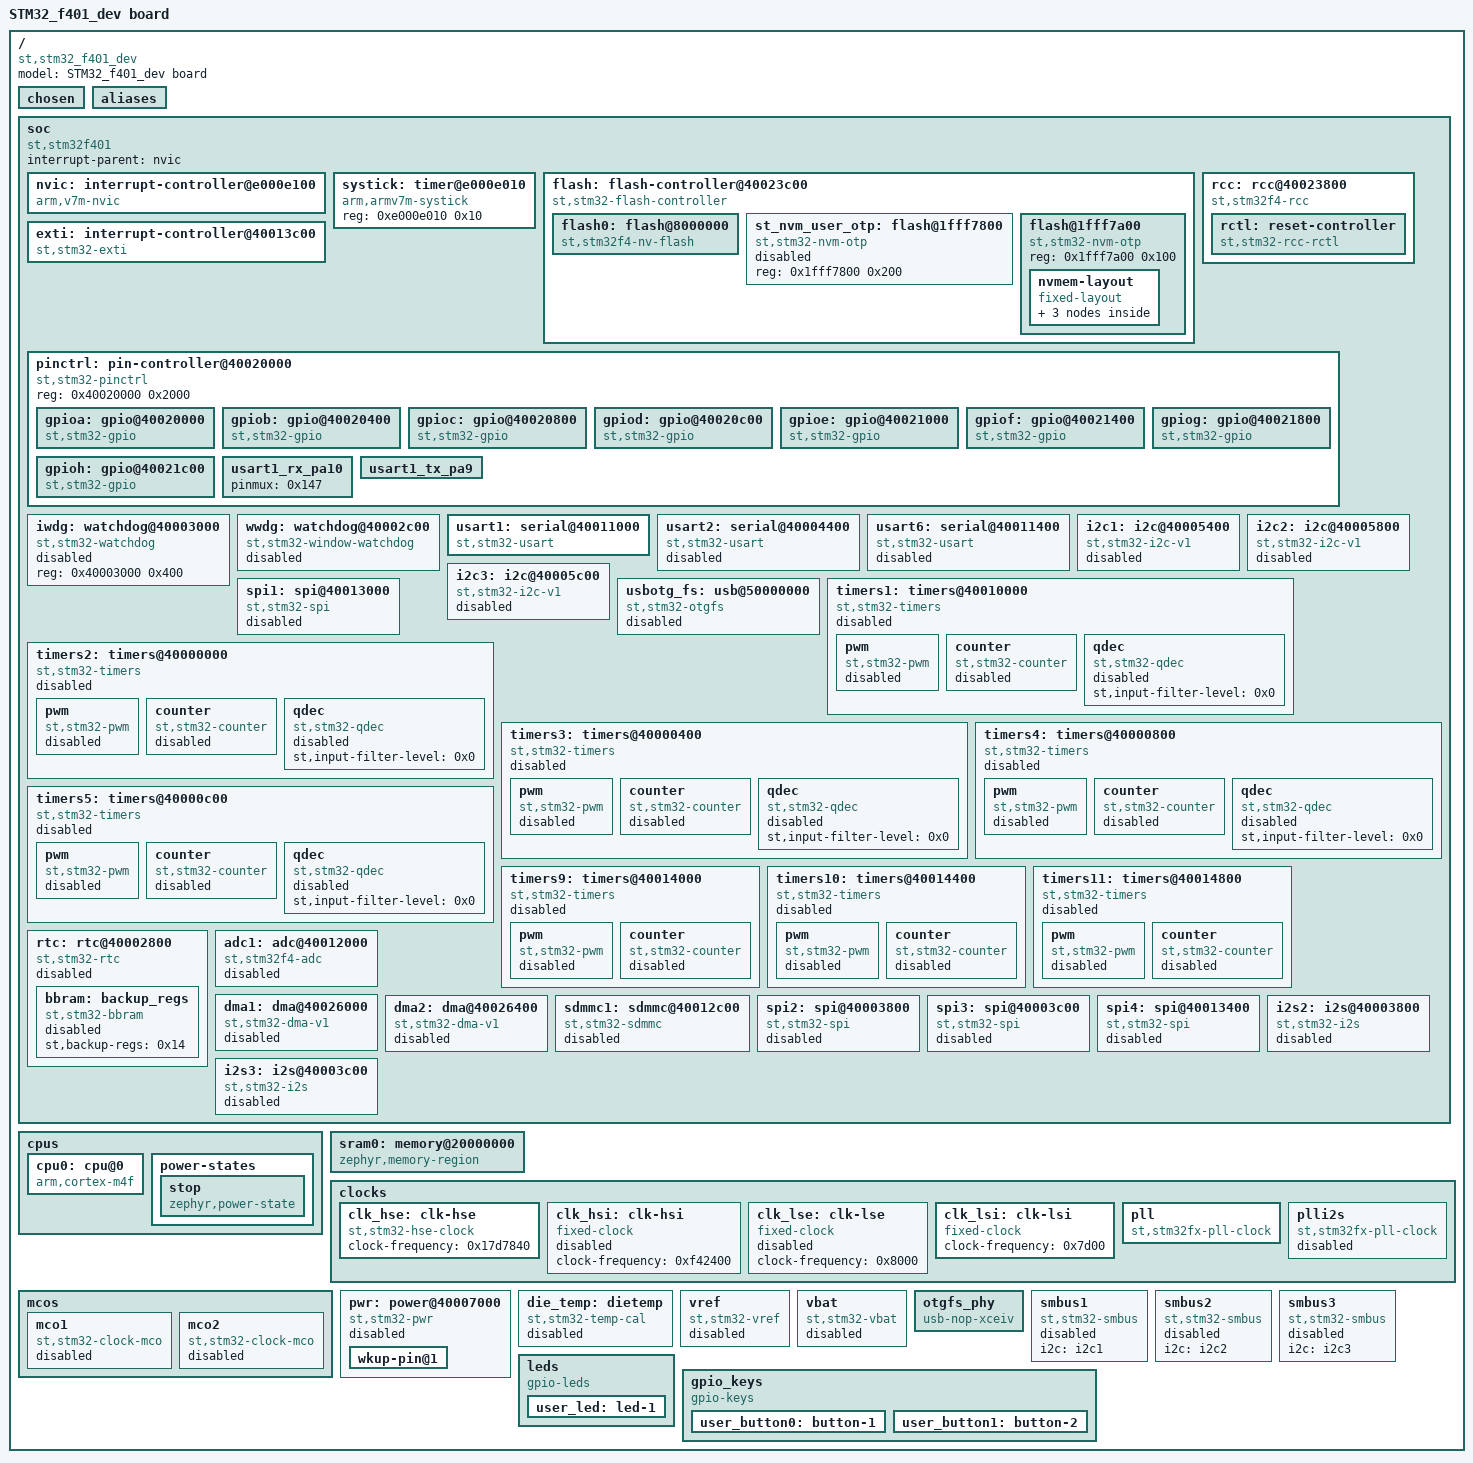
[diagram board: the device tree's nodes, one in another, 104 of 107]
/dts-v1/;

/* node '/' defined in zephyr/dts/common/skeleton.dtsi:9 */
/ {
	#address-cells = < 0x1 >;         /* in zephyr/dts/common/skeleton.dtsi:10 */
	#size-cells = < 0x1 >;            /* in zephyr/dts/common/skeleton.dtsi:11 */
	model = "STM32_f401_dev board";   /* in ../STM32_F401_Basic_Framework/boards/others/stm32_f401_dev/stm32_f401_dev.dts:8 */
	compatible = "st,stm32_f401_dev"; /* in ../STM32_F401_Basic_Framework/boards/others/stm32_f401_dev/stm32_f401_dev.dts:9 */

	/* node '/chosen' defined in zephyr/dts/common/skeleton.dtsi:13 */
	chosen {
		zephyr,flash-controller = &flash;     /* in zephyr/dts/arm/st/f4/stm32f4.dtsi:26 */
		zephyr,system-timer-companion = &rtc; /* in zephyr/dts/arm/st/f4/stm32f4.dtsi:27 */
		zephyr,console = &usart1;             /* in ../STM32_F401_Basic_Framework/boards/others/stm32_f401_dev/stm32_f401_dev.dts:12 */
		zephyr,shell-uart = &usart1;          /* in ../STM32_F401_Basic_Framework/boards/others/stm32_f401_dev/stm32_f401_dev.dts:13 */
		zephyr,sram = &sram0;                 /* in ../STM32_F401_Basic_Framework/boards/others/stm32_f401_dev/stm32_f401_dev.dts:14 */
		zephyr,flash = &flash0;               /* in ../STM32_F401_Basic_Framework/boards/others/stm32_f401_dev/stm32_f401_dev.dts:15 */
	};

	/* node '/aliases' defined in zephyr/dts/common/skeleton.dtsi:15 */
	aliases {
		led0 = &user_led;    /* in ../STM32_F401_Basic_Framework/boards/others/stm32_f401_dev/stm32_f401_dev.dts:19 */
		sw0 = &user_button0; /* in ../STM32_F401_Basic_Framework/boards/others/stm32_f401_dev/stm32_f401_dev.dts:20 */
		sw1 = &user_button1; /* in ../STM32_F401_Basic_Framework/boards/others/stm32_f401_dev/stm32_f401_dev.dts:21 */
	};

	/* node '/soc' defined in zephyr/dts/arm/armv7-m.dtsi:6 */
	soc {
		#address-cells = < 0x1 >;     /* in zephyr/dts/arm/armv7-m.dtsi:7 */
		#size-cells = < 0x1 >;        /* in zephyr/dts/arm/armv7-m.dtsi:8 */
		interrupt-parent = < &nvic >; /* in zephyr/dts/arm/armv7-m.dtsi:10 */
		ranges;                       /* in zephyr/dts/arm/armv7-m.dtsi:11 */
		compatible = "st,stm32f401",
		             "st,stm32f4",
		             "simple-bus";    /* in zephyr/dts/arm/st/f4/stm32f401.dtsi:19 */

		/* node '/soc/interrupt-controller@e000e100' defined in zephyr/dts/arm/armv7-m.dtsi:13 */
		nvic: interrupt-controller@e000e100 {
			#address-cells = < 0x1 >;            /* in zephyr/dts/arm/armv7-m.dtsi:14 */
			compatible = "arm,v7m-nvic";         /* in zephyr/dts/arm/armv7-m.dtsi:15 */
			reg = < 0xe000e100 0xc00 >;          /* in zephyr/dts/arm/armv7-m.dtsi:16 */
			interrupt-controller;                /* in zephyr/dts/arm/armv7-m.dtsi:17 */
			#interrupt-cells = < 0x2 >;          /* in zephyr/dts/arm/armv7-m.dtsi:18 */
			arm,num-irq-priority-bits = < 0x4 >; /* in zephyr/dts/arm/st/f4/stm32f4.dtsi:730 */
			phandle = < 0x1 >;                   /* in zephyr/dts/arm/armv7-m.dtsi:10 */
		};

		/* node '/soc/timer@e000e010' defined in zephyr/dts/arm/armv7-m.dtsi:21 */
		systick: timer@e000e010 {
			compatible = "arm,armv7m-systick"; /* in zephyr/dts/arm/armv7-m.dtsi:22 */
			reg = < 0xe000e010 0x10 >;         /* in zephyr/dts/arm/armv7-m.dtsi:23 */
		};

		/* node '/soc/flash-controller@40023c00' defined in zephyr/dts/arm/st/f4/stm32f4.dtsi:112 */
		flash: flash-controller@40023c00 {
			compatible = "st,stm32-flash-controller",
			             "st,stm32f4-flash-controller"; /* in zephyr/dts/arm/st/f4/stm32f4.dtsi:113 */
			reg = < 0x40023c00 0x400 >;                 /* in zephyr/dts/arm/st/f4/stm32f4.dtsi:114 */
			interrupts = < 0x4 0x0 >;                   /* in zephyr/dts/arm/st/f4/stm32f4.dtsi:115 */
			#address-cells = < 0x1 >;                   /* in zephyr/dts/arm/st/f4/stm32f4.dtsi:117 */
			#size-cells = < 0x1 >;                      /* in zephyr/dts/arm/st/f4/stm32f4.dtsi:118 */
			ranges;                                     /* in zephyr/dts/arm/st/f4/stm32f4.dtsi:119 */

			/* node '/soc/flash-controller@40023c00/flash@8000000' defined in zephyr/dts/arm/st/f4/stm32f4.dtsi:121 */
			flash0: flash@8000000 {
				compatible = "st,stm32f4-nv-flash",
				             "st,stm32-nv-flash",
				             "soc-nv-flash";        /* in zephyr/dts/arm/st/f4/stm32f4.dtsi:122 */
				#address-cells = < 0x1 >;           /* in zephyr/dts/arm/st/f4/stm32f4.dtsi:124 */
				#size-cells = < 0x1 >;              /* in zephyr/dts/arm/st/f4/stm32f4.dtsi:125 */
				write-block-size = < 0x1 >;         /* in zephyr/dts/arm/st/f4/stm32f4.dtsi:126 */
				max-erase-time = < 0xfa0 >;         /* in zephyr/dts/arm/st/f4/stm32f4.dtsi:128 */
				reg = < 0x8000000 0x80000 >;        /* in zephyr/dts/arm/st/f4/stm32f401Xe.dtsi:17 */
				ranges = < 0x0 0x8000000 0x80000 >; /* in zephyr/dts/arm/st/f4/stm32f401Xe.dtsi:18 */
			};

			/* node '/soc/flash-controller@40023c00/flash@1fff7800' defined in zephyr/dts/arm/st/f4/stm32f4.dtsi:131 */
			st_nvm_user_otp: flash@1fff7800 {
				compatible = "st,stm32-nvm-otp"; /* in zephyr/dts/arm/st/f4/stm32f4.dtsi:132 */
				reg = < 0x1fff7800 0x200 >;      /* in zephyr/dts/arm/st/f4/stm32f4.dtsi:133 */
				status = "disabled";             /* in zephyr/dts/arm/st/f4/stm32f4.dtsi:134 */
			};

			/* node '/soc/flash-controller@40023c00/flash@1fff7a00' defined in zephyr/dts/arm/st/f4/stm32f4.dtsi:148 */
			flash@1fff7a00 {
				compatible = "st,stm32-nvm-otp"; /* in zephyr/dts/arm/st/f4/stm32f4.dtsi:149 */
				reg = < 0x1fff7a00 0x100 >;      /* in zephyr/dts/arm/st/f4/stm32f4.dtsi:150 */

				/* node '/soc/flash-controller@40023c00/flash@1fff7a00/nvmem-layout' defined in zephyr/dts/arm/st/f4/stm32f4.dtsi:152 */
				nvmem-layout {
					compatible = "fixed-layout"; /* in zephyr/dts/arm/st/f4/stm32f4.dtsi:153 */
					#address-cells = < 0x1 >;    /* in zephyr/dts/arm/st/f4/stm32f4.dtsi:154 */
					#size-cells = < 0x1 >;       /* in zephyr/dts/arm/st/f4/stm32f4.dtsi:155 */

					/* node '/soc/flash-controller@40023c00/flash@1fff7a00/nvmem-layout/vrefint@2a' defined in zephyr/dts/arm/st/f4/stm32f4.dtsi:157 */
					vrefint_otp: vrefint@2a {
						reg = < 0x2a 0x2 >;          /* in zephyr/dts/arm/st/f4/stm32f4.dtsi:158 */
						#nvmem-cell-cells = < 0x0 >; /* in zephyr/dts/arm/st/f4/stm32f4.dtsi:159 */
						read-only;                   /* in zephyr/dts/arm/st/f4/stm32f4.dtsi:160 */
						phandle = < 0xf >;           /* in zephyr/dts/arm/st/f4/stm32f4.dtsi:686 */
					};

					/* node '/soc/flash-controller@40023c00/flash@1fff7a00/nvmem-layout/ts-cal1@2c' defined in zephyr/dts/arm/st/f4/stm32f4.dtsi:163 */
					ts_cal1_otp: ts-cal1@2c {
						reg = < 0x2c 0x2 >;          /* in zephyr/dts/arm/st/f4/stm32f4.dtsi:164 */
						#nvmem-cell-cells = < 0x0 >; /* in zephyr/dts/arm/st/f4/stm32f4.dtsi:165 */
						read-only;                   /* in zephyr/dts/arm/st/f4/stm32f4.dtsi:166 */
						phandle = < 0xc >;           /* in zephyr/dts/arm/st/f4/stm32f4.dtsi:675 */
					};

					/* node '/soc/flash-controller@40023c00/flash@1fff7a00/nvmem-layout/ts-cal2@2e' defined in zephyr/dts/arm/st/f4/stm32f4.dtsi:169 */
					ts_cal2_otp: ts-cal2@2e {
						reg = < 0x2e 0x2 >;          /* in zephyr/dts/arm/st/f4/stm32f4.dtsi:170 */
						#nvmem-cell-cells = < 0x0 >; /* in zephyr/dts/arm/st/f4/stm32f4.dtsi:171 */
						read-only;                   /* in zephyr/dts/arm/st/f4/stm32f4.dtsi:172 */
						phandle = < 0xd >;           /* in zephyr/dts/arm/st/f4/stm32f4.dtsi:675 */
					};
				};
			};
		};

		/* node '/soc/rcc@40023800' defined in zephyr/dts/arm/st/f4/stm32f4.dtsi:178 */
		rcc: rcc@40023800 {
			compatible = "st,stm32f4-rcc";   /* in zephyr/dts/arm/st/f4/stm32f4.dtsi:179 */
			#clock-cells = < 0x2 >;          /* in zephyr/dts/arm/st/f4/stm32f4.dtsi:180 */
			reg = < 0x40023800 0x400 >;      /* in zephyr/dts/arm/st/f4/stm32f4.dtsi:181 */
			clocks = < &pll >;               /* in ../STM32_F401_Basic_Framework/boards/others/stm32_f401_dev/stm32_f401_dev.dts:69 */
			clock-frequency = < 0x501bd00 >; /* in ../STM32_F401_Basic_Framework/boards/others/stm32_f401_dev/stm32_f401_dev.dts:70 */
			ahb-prescaler = < 0x1 >;         /* in ../STM32_F401_Basic_Framework/boards/others/stm32_f401_dev/stm32_f401_dev.dts:71 */
			apb1-prescaler = < 0x2 >;        /* in ../STM32_F401_Basic_Framework/boards/others/stm32_f401_dev/stm32_f401_dev.dts:72 */
			apb2-prescaler = < 0x1 >;        /* in ../STM32_F401_Basic_Framework/boards/others/stm32_f401_dev/stm32_f401_dev.dts:73 */
			phandle = < 0x3 >;               /* in zephyr/dts/arm/st/f4/stm32f4.dtsi:195 */

			/* node '/soc/rcc@40023800/reset-controller' defined in zephyr/dts/arm/st/f4/stm32f4.dtsi:183 */
			rctl: reset-controller {
				compatible = "st,stm32-rcc-rctl"; /* in zephyr/dts/arm/st/f4/stm32f4.dtsi:184 */
				#reset-cells = < 0x1 >;           /* in zephyr/dts/arm/st/f4/stm32f4.dtsi:185 */
				phandle = < 0x4 >;                /* in zephyr/dts/arm/st/f4/stm32f4.dtsi:295 */
			};
		};

		/* node '/soc/interrupt-controller@40013c00' defined in zephyr/dts/arm/st/f4/stm32f4.dtsi:189 */
		exti: interrupt-controller@40013c00 {
			compatible = "st,stm32-exti";  /* in zephyr/dts/arm/st/f4/stm32f4.dtsi:190 */
			interrupt-controller;          /* in zephyr/dts/arm/st/f4/stm32f4.dtsi:191 */
			#interrupt-cells = < 0x1 >;    /* in zephyr/dts/arm/st/f4/stm32f4.dtsi:192 */
			#address-cells = < 0x0 >;      /* in zephyr/dts/arm/st/f4/stm32f4.dtsi:193 */
			reg = < 0x40013c00 0x400 >;    /* in zephyr/dts/arm/st/f4/stm32f4.dtsi:194 */
			clocks = < &rcc 0x44 0x4000 >; /* in zephyr/dts/arm/st/f4/stm32f4.dtsi:195 */
			num-lines = < 0x20 >;          /* in zephyr/dts/arm/st/f4/stm32f4.dtsi:196 */
			interrupts = < 0x6 0x0 >,
			             < 0x7 0x0 >,
			             < 0x8 0x0 >,
			             < 0x9 0x0 >,
			             < 0xa 0x0 >,
			             < 0x17 0x0 >,
			             < 0x28 0x0 >;     /* in zephyr/dts/arm/st/f4/stm32f4.dtsi:197 */
			interrupt-names = "line0",
			                  "line1",
			                  "line2",
			                  "line3",
			                  "line4",
			                  "line5-9",
			                  "line10-15"; /* in zephyr/dts/arm/st/f4/stm32f4.dtsi:199 */
			line-ranges = < 0x0 0x1 >,
			              < 0x1 0x1 >,
			              < 0x2 0x1 >,
			              < 0x3 0x1 >,
			              < 0x4 0x1 >,
			              < 0x5 0x5 >,
			              < 0xa 0x6 >;     /* in zephyr/dts/arm/st/f4/stm32f4.dtsi:201 */
		};

		/* node '/soc/pin-controller@40020000' defined in zephyr/dts/arm/st/f4/stm32f4.dtsi:205 */
		pinctrl: pin-controller@40020000 {
			compatible = "st,stm32-pinctrl"; /* in zephyr/dts/arm/st/f4/stm32f4.dtsi:206 */
			#address-cells = < 0x1 >;        /* in zephyr/dts/arm/st/f4/stm32f4.dtsi:207 */
			#size-cells = < 0x1 >;           /* in zephyr/dts/arm/st/f4/stm32f4.dtsi:208 */
			reg = < 0x40020000 0x2000 >;     /* in zephyr/dts/arm/st/f4/stm32f4.dtsi:209 */
			ranges;                          /* in zephyr/dts/arm/st/f4/stm32f4.dtsi:210 */

			/* node '/soc/pin-controller@40020000/gpio@40020000' defined in zephyr/dts/arm/st/f4/stm32f4.dtsi:212 */
			gpioa: gpio@40020000 {
				compatible = "st,stm32-gpio"; /* in zephyr/dts/arm/st/f4/stm32f4.dtsi:213 */
				gpio-controller;              /* in zephyr/dts/arm/st/f4/stm32f4.dtsi:214 */
				#gpio-cells = < 0x2 >;        /* in zephyr/dts/arm/st/f4/stm32f4.dtsi:215 */
				reg = < 0x40020000 0x400 >;   /* in zephyr/dts/arm/st/f4/stm32f4.dtsi:216 */
				clocks = < &rcc 0x30 0x1 >;   /* in zephyr/dts/arm/st/f4/stm32f4.dtsi:217 */
				phandle = < 0xb >;            /* in zephyr/dts/arm/st/f4/stm32f4.dtsi:669 */
			};

			/* node '/soc/pin-controller@40020000/gpio@40020400' defined in zephyr/dts/arm/st/f4/stm32f4.dtsi:220 */
			gpiob: gpio@40020400 {
				compatible = "st,stm32-gpio"; /* in zephyr/dts/arm/st/f4/stm32f4.dtsi:221 */
				gpio-controller;              /* in zephyr/dts/arm/st/f4/stm32f4.dtsi:222 */
				#gpio-cells = < 0x2 >;        /* in zephyr/dts/arm/st/f4/stm32f4.dtsi:223 */
				reg = < 0x40020400 0x400 >;   /* in zephyr/dts/arm/st/f4/stm32f4.dtsi:224 */
				clocks = < &rcc 0x30 0x2 >;   /* in zephyr/dts/arm/st/f4/stm32f4.dtsi:225 */
			};

			/* node '/soc/pin-controller@40020000/gpio@40020800' defined in zephyr/dts/arm/st/f4/stm32f4.dtsi:228 */
			gpioc: gpio@40020800 {
				compatible = "st,stm32-gpio"; /* in zephyr/dts/arm/st/f4/stm32f4.dtsi:229 */
				gpio-controller;              /* in zephyr/dts/arm/st/f4/stm32f4.dtsi:230 */
				#gpio-cells = < 0x2 >;        /* in zephyr/dts/arm/st/f4/stm32f4.dtsi:231 */
				reg = < 0x40020800 0x400 >;   /* in zephyr/dts/arm/st/f4/stm32f4.dtsi:232 */
				clocks = < &rcc 0x30 0x4 >;   /* in zephyr/dts/arm/st/f4/stm32f4.dtsi:233 */
				phandle = < 0x13 >;           /* in ../STM32_F401_Basic_Framework/boards/others/stm32_f401_dev/stm32_f401_dev.dts:28 */
			};

			/* node '/soc/pin-controller@40020000/gpio@40020c00' defined in zephyr/dts/arm/st/f4/stm32f4.dtsi:236 */
			gpiod: gpio@40020c00 {
				compatible = "st,stm32-gpio"; /* in zephyr/dts/arm/st/f4/stm32f4.dtsi:237 */
				gpio-controller;              /* in zephyr/dts/arm/st/f4/stm32f4.dtsi:238 */
				#gpio-cells = < 0x2 >;        /* in zephyr/dts/arm/st/f4/stm32f4.dtsi:239 */
				reg = < 0x40020c00 0x400 >;   /* in zephyr/dts/arm/st/f4/stm32f4.dtsi:240 */
				clocks = < &rcc 0x30 0x8 >;   /* in zephyr/dts/arm/st/f4/stm32f4.dtsi:241 */
			};

			/* node '/soc/pin-controller@40020000/gpio@40021000' defined in zephyr/dts/arm/st/f4/stm32f4.dtsi:244 */
			gpioe: gpio@40021000 {
				compatible = "st,stm32-gpio"; /* in zephyr/dts/arm/st/f4/stm32f4.dtsi:245 */
				gpio-controller;              /* in zephyr/dts/arm/st/f4/stm32f4.dtsi:246 */
				#gpio-cells = < 0x2 >;        /* in zephyr/dts/arm/st/f4/stm32f4.dtsi:247 */
				reg = < 0x40021000 0x400 >;   /* in zephyr/dts/arm/st/f4/stm32f4.dtsi:248 */
				clocks = < &rcc 0x30 0x10 >;  /* in zephyr/dts/arm/st/f4/stm32f4.dtsi:249 */
			};

			/* node '/soc/pin-controller@40020000/gpio@40021400' defined in zephyr/dts/arm/st/f4/stm32f4.dtsi:252 */
			gpiof: gpio@40021400 {
				compatible = "st,stm32-gpio"; /* in zephyr/dts/arm/st/f4/stm32f4.dtsi:253 */
				gpio-controller;              /* in zephyr/dts/arm/st/f4/stm32f4.dtsi:254 */
				#gpio-cells = < 0x2 >;        /* in zephyr/dts/arm/st/f4/stm32f4.dtsi:255 */
				reg = < 0x40021400 0x400 >;   /* in zephyr/dts/arm/st/f4/stm32f4.dtsi:256 */
				clocks = < &rcc 0x30 0x20 >;  /* in zephyr/dts/arm/st/f4/stm32f4.dtsi:257 */
			};

			/* node '/soc/pin-controller@40020000/gpio@40021800' defined in zephyr/dts/arm/st/f4/stm32f4.dtsi:260 */
			gpiog: gpio@40021800 {
				compatible = "st,stm32-gpio"; /* in zephyr/dts/arm/st/f4/stm32f4.dtsi:261 */
				gpio-controller;              /* in zephyr/dts/arm/st/f4/stm32f4.dtsi:262 */
				#gpio-cells = < 0x2 >;        /* in zephyr/dts/arm/st/f4/stm32f4.dtsi:263 */
				reg = < 0x40021800 0x400 >;   /* in zephyr/dts/arm/st/f4/stm32f4.dtsi:264 */
				clocks = < &rcc 0x30 0x40 >;  /* in zephyr/dts/arm/st/f4/stm32f4.dtsi:265 */
			};

			/* node '/soc/pin-controller@40020000/gpio@40021c00' defined in zephyr/dts/arm/st/f4/stm32f4.dtsi:268 */
			gpioh: gpio@40021c00 {
				compatible = "st,stm32-gpio"; /* in zephyr/dts/arm/st/f4/stm32f4.dtsi:269 */
				gpio-controller;              /* in zephyr/dts/arm/st/f4/stm32f4.dtsi:270 */
				#gpio-cells = < 0x2 >;        /* in zephyr/dts/arm/st/f4/stm32f4.dtsi:271 */
				reg = < 0x40021c00 0x400 >;   /* in zephyr/dts/arm/st/f4/stm32f4.dtsi:272 */
				clocks = < &rcc 0x30 0x80 >;  /* in zephyr/dts/arm/st/f4/stm32f4.dtsi:273 */
			};

			/* node '/soc/pin-controller@40020000/usart1_rx_pa10' defined in modules/hal/stm32/dts/st/f4/stm32f401r(d-e)tx-pinctrl.dtsi:870 */
			usart1_rx_pa10: usart1_rx_pa10 {
				pinmux = < 0x147 >; /* in modules/hal/stm32/dts/st/f4/stm32f401r(d-e)tx-pinctrl.dtsi:871 */
				phandle = < 0x6 >;  /* in ../STM32_F401_Basic_Framework/boards/others/stm32_f401_dev/stm32_f401_dev.dts:77 */
			};

			/* node '/soc/pin-controller@40020000/usart1_tx_pa9' defined in modules/hal/stm32/dts/st/f4/stm32f401r(d-e)tx-pinctrl.dtsi:892 */
			usart1_tx_pa9: usart1_tx_pa9 {
				pinmux = < 0x127 >; /* in modules/hal/stm32/dts/st/f4/stm32f401r(d-e)tx-pinctrl.dtsi:893 */
				bias-pull-up;       /* in modules/hal/stm32/dts/st/f4/stm32f401r(d-e)tx-pinctrl.dtsi:894 */
				phandle = < 0x5 >;  /* in ../STM32_F401_Basic_Framework/boards/others/stm32_f401_dev/stm32_f401_dev.dts:77 */
			};
		};

		/* node '/soc/watchdog@40003000' defined in zephyr/dts/arm/st/f4/stm32f4.dtsi:277 */
		iwdg: watchdog@40003000 {
			compatible = "st,stm32-watchdog"; /* in zephyr/dts/arm/st/f4/stm32f4.dtsi:278 */
			reg = < 0x40003000 0x400 >;       /* in zephyr/dts/arm/st/f4/stm32f4.dtsi:279 */
			status = "disabled";              /* in zephyr/dts/arm/st/f4/stm32f4.dtsi:280 */
		};

		/* node '/soc/watchdog@40002c00' defined in zephyr/dts/arm/st/f4/stm32f4.dtsi:283 */
		wwdg: watchdog@40002c00 {
			compatible = "st,stm32-window-watchdog"; /* in zephyr/dts/arm/st/f4/stm32f4.dtsi:284 */
			reg = < 0x40002c00 0x400 >;              /* in zephyr/dts/arm/st/f4/stm32f4.dtsi:285 */
			clocks = < &rcc 0x40 0x800 >;            /* in zephyr/dts/arm/st/f4/stm32f4.dtsi:286 */
			interrupts = < 0x0 0x0 >;                /* in zephyr/dts/arm/st/f4/stm32f4.dtsi:287 */
			status = "disabled";                     /* in zephyr/dts/arm/st/f4/stm32f4.dtsi:288 */
		};

		/* node '/soc/serial@40011000' defined in zephyr/dts/arm/st/f4/stm32f4.dtsi:291 */
		usart1: serial@40011000 {
			compatible = "st,stm32-usart",
			             "st,stm32-uart";                   /* in zephyr/dts/arm/st/f4/stm32f4.dtsi:292 */
			reg = < 0x40011000 0x400 >;                     /* in zephyr/dts/arm/st/f4/stm32f4.dtsi:293 */
			clocks = < &rcc 0x44 0x10 >;                    /* in zephyr/dts/arm/st/f4/stm32f4.dtsi:294 */
			resets = < &rctl 0x484 >;                       /* in zephyr/dts/arm/st/f4/stm32f4.dtsi:295 */
			interrupts = < 0x25 0x0 >;                      /* in zephyr/dts/arm/st/f4/stm32f4.dtsi:296 */
			pinctrl-0 = < &usart1_tx_pa9 &usart1_rx_pa10 >; /* in ../STM32_F401_Basic_Framework/boards/others/stm32_f401_dev/stm32_f401_dev.dts:77 */
			pinctrl-names = "default";                      /* in ../STM32_F401_Basic_Framework/boards/others/stm32_f401_dev/stm32_f401_dev.dts:78 */
			current-speed = < 0x1c200 >;                    /* in ../STM32_F401_Basic_Framework/boards/others/stm32_f401_dev/stm32_f401_dev.dts:79 */
			status = "okay";                                /* in ../STM32_F401_Basic_Framework/boards/others/stm32_f401_dev/stm32_f401_dev.dts:80 */
		};

		/* node '/soc/serial@40004400' defined in zephyr/dts/arm/st/f4/stm32f4.dtsi:300 */
		usart2: serial@40004400 {
			compatible = "st,stm32-usart",
			             "st,stm32-uart";   /* in zephyr/dts/arm/st/f4/stm32f4.dtsi:301 */
			reg = < 0x40004400 0x400 >;     /* in zephyr/dts/arm/st/f4/stm32f4.dtsi:302 */
			clocks = < &rcc 0x40 0x20000 >; /* in zephyr/dts/arm/st/f4/stm32f4.dtsi:303 */
			resets = < &rctl 0x411 >;       /* in zephyr/dts/arm/st/f4/stm32f4.dtsi:304 */
			interrupts = < 0x26 0x0 >;      /* in zephyr/dts/arm/st/f4/stm32f4.dtsi:305 */
			status = "disabled";            /* in zephyr/dts/arm/st/f4/stm32f4.dtsi:306 */
		};

		/* node '/soc/serial@40011400' defined in zephyr/dts/arm/st/f4/stm32f4.dtsi:309 */
		usart6: serial@40011400 {
			compatible = "st,stm32-usart",
			             "st,stm32-uart";  /* in zephyr/dts/arm/st/f4/stm32f4.dtsi:310 */
			reg = < 0x40011400 0x400 >;    /* in zephyr/dts/arm/st/f4/stm32f4.dtsi:311 */
			clocks = < &rcc 0x44 0x20 >;   /* in zephyr/dts/arm/st/f4/stm32f4.dtsi:312 */
			resets = < &rctl 0x485 >;      /* in zephyr/dts/arm/st/f4/stm32f4.dtsi:313 */
			interrupts = < 0x47 0x0 >;     /* in zephyr/dts/arm/st/f4/stm32f4.dtsi:314 */
			status = "disabled";           /* in zephyr/dts/arm/st/f4/stm32f4.dtsi:315 */
		};

		/* node '/soc/i2c@40005400' defined in zephyr/dts/arm/st/f4/stm32f4.dtsi:318 */
		i2c1: i2c@40005400 {
			compatible = "st,stm32-i2c-v1";  /* in zephyr/dts/arm/st/f4/stm32f4.dtsi:319 */
			clock-frequency = < 0x186a0 >;   /* in zephyr/dts/arm/st/f4/stm32f4.dtsi:320 */
			#address-cells = < 0x1 >;        /* in zephyr/dts/arm/st/f4/stm32f4.dtsi:321 */
			#size-cells = < 0x0 >;           /* in zephyr/dts/arm/st/f4/stm32f4.dtsi:322 */
			reg = < 0x40005400 0x400 >;      /* in zephyr/dts/arm/st/f4/stm32f4.dtsi:323 */
			clocks = < &rcc 0x40 0x200000 >; /* in zephyr/dts/arm/st/f4/stm32f4.dtsi:324 */
			interrupts = < 0x1f 0x0 >,
			             < 0x20 0x0 >;       /* in zephyr/dts/arm/st/f4/stm32f4.dtsi:325 */
			interrupt-names = "event",
			                  "error";       /* in zephyr/dts/arm/st/f4/stm32f4.dtsi:326 */
			status = "disabled";             /* in zephyr/dts/arm/st/f4/stm32f4.dtsi:327 */
			phandle = < 0x10 >;              /* in zephyr/dts/arm/st/f4/stm32f4.dtsi:708 */
		};

		/* node '/soc/i2c@40005800' defined in zephyr/dts/arm/st/f4/stm32f4.dtsi:330 */
		i2c2: i2c@40005800 {
			compatible = "st,stm32-i2c-v1";  /* in zephyr/dts/arm/st/f4/stm32f4.dtsi:331 */
			clock-frequency = < 0x186a0 >;   /* in zephyr/dts/arm/st/f4/stm32f4.dtsi:332 */
			#address-cells = < 0x1 >;        /* in zephyr/dts/arm/st/f4/stm32f4.dtsi:333 */
			#size-cells = < 0x0 >;           /* in zephyr/dts/arm/st/f4/stm32f4.dtsi:334 */
			reg = < 0x40005800 0x400 >;      /* in zephyr/dts/arm/st/f4/stm32f4.dtsi:335 */
			clocks = < &rcc 0x40 0x400000 >; /* in zephyr/dts/arm/st/f4/stm32f4.dtsi:336 */
			interrupts = < 0x21 0x0 >,
			             < 0x22 0x0 >;       /* in zephyr/dts/arm/st/f4/stm32f4.dtsi:337 */
			interrupt-names = "event",
			                  "error";       /* in zephyr/dts/arm/st/f4/stm32f4.dtsi:338 */
			status = "disabled";             /* in zephyr/dts/arm/st/f4/stm32f4.dtsi:339 */
			phandle = < 0x11 >;              /* in zephyr/dts/arm/st/f4/stm32f4.dtsi:716 */
		};

		/* node '/soc/i2c@40005c00' defined in zephyr/dts/arm/st/f4/stm32f4.dtsi:342 */
		i2c3: i2c@40005c00 {
			compatible = "st,stm32-i2c-v1";  /* in zephyr/dts/arm/st/f4/stm32f4.dtsi:343 */
			clock-frequency = < 0x186a0 >;   /* in zephyr/dts/arm/st/f4/stm32f4.dtsi:344 */
			#address-cells = < 0x1 >;        /* in zephyr/dts/arm/st/f4/stm32f4.dtsi:345 */
			#size-cells = < 0x0 >;           /* in zephyr/dts/arm/st/f4/stm32f4.dtsi:346 */
			reg = < 0x40005c00 0x400 >;      /* in zephyr/dts/arm/st/f4/stm32f4.dtsi:347 */
			clocks = < &rcc 0x40 0x800000 >; /* in zephyr/dts/arm/st/f4/stm32f4.dtsi:348 */
			interrupts = < 0x48 0x0 >,
			             < 0x49 0x0 >;       /* in zephyr/dts/arm/st/f4/stm32f4.dtsi:349 */
			interrupt-names = "event",
			                  "error";       /* in zephyr/dts/arm/st/f4/stm32f4.dtsi:350 */
			status = "disabled";             /* in zephyr/dts/arm/st/f4/stm32f4.dtsi:351 */
			phandle = < 0x12 >;              /* in zephyr/dts/arm/st/f4/stm32f4.dtsi:724 */
		};

		/* node '/soc/spi@40013000' defined in zephyr/dts/arm/st/f4/stm32f4.dtsi:354 */
		spi1: spi@40013000 {
			compatible = "st,stm32-spi";            /* in zephyr/dts/arm/st/f4/stm32f4.dtsi:355 */
			#address-cells = < 0x1 >;               /* in zephyr/dts/arm/st/f4/stm32f4.dtsi:356 */
			#size-cells = < 0x0 >;                  /* in zephyr/dts/arm/st/f4/stm32f4.dtsi:357 */
			reg = < 0x40013000 0x400 >;             /* in zephyr/dts/arm/st/f4/stm32f4.dtsi:358 */
			clocks = < &rcc 0x44 0x1000 >;          /* in zephyr/dts/arm/st/f4/stm32f4.dtsi:359 */
			interrupts = < 0x23 0x0 >;              /* in zephyr/dts/arm/st/f4/stm32f4.dtsi:360 */
			st,spi-data-width = "limited-8-16-bit"; /* in zephyr/dts/arm/st/f4/stm32f4.dtsi:361 */
			status = "disabled";                    /* in zephyr/dts/arm/st/f4/stm32f4.dtsi:362 */
		};

		/* node '/soc/usb@50000000' defined in zephyr/dts/arm/st/f4/stm32f4.dtsi:365 */
		usbotg_fs: usb@50000000 {
			compatible = "st,stm32-otgfs"; /* in zephyr/dts/arm/st/f4/stm32f4.dtsi:366 */
			reg = < 0x50000000 0x40000 >;  /* in zephyr/dts/arm/st/f4/stm32f4.dtsi:367 */
			interrupts = < 0x43 0x0 >;     /* in zephyr/dts/arm/st/f4/stm32f4.dtsi:368 */
			interrupt-names = "otgfs";     /* in zephyr/dts/arm/st/f4/stm32f4.dtsi:369 */
			num-bidir-endpoints = < 0x4 >; /* in zephyr/dts/arm/st/f4/stm32f4.dtsi:370 */
			ram-size = < 0x500 >;          /* in zephyr/dts/arm/st/f4/stm32f4.dtsi:371 */
			maximum-speed = "full-speed";  /* in zephyr/dts/arm/st/f4/stm32f4.dtsi:372 */
			phys = < &otgfs_phy >;         /* in zephyr/dts/arm/st/f4/stm32f4.dtsi:373 */
			clocks = < &rcc 0x34 0x80 >,
			         < &rcc 0x7 0xff >;    /* in zephyr/dts/arm/st/f4/stm32f4.dtsi:374 */
			status = "disabled";           /* in zephyr/dts/arm/st/f4/stm32f4.dtsi:376 */
		};

		/* node '/soc/timers@40010000' defined in zephyr/dts/arm/st/f4/stm32f4.dtsi:379 */
		timers1: timers@40010000 {
			compatible = "st,stm32-timers"; /* in zephyr/dts/arm/st/f4/stm32f4.dtsi:380 */
			reg = < 0x40010000 0x400 >;     /* in zephyr/dts/arm/st/f4/stm32f4.dtsi:381 */
			clocks = < &rcc 0x44 0x1 >,
			         < &rcc 0x16 0xff >;    /* in zephyr/dts/arm/st/f4/stm32f4.dtsi:382 */
			resets = < &rctl 0x480 >;       /* in zephyr/dts/arm/st/f4/stm32f4.dtsi:384 */
			interrupts = < 0x18 0x0 >,
			             < 0x19 0x0 >,
			             < 0x1a 0x0 >,
			             < 0x1b 0x0 >;      /* in zephyr/dts/arm/st/f4/stm32f4.dtsi:385 */
			interrupt-names = "brk",
			                  "up",
			                  "trgcom",
			                  "cc";         /* in zephyr/dts/arm/st/f4/stm32f4.dtsi:386 */
			st,prescaler = < 0x0 >;         /* in zephyr/dts/arm/st/f4/stm32f4.dtsi:387 */
			status = "disabled";            /* in zephyr/dts/arm/st/f4/stm32f4.dtsi:388 */

			/* node '/soc/timers@40010000/pwm' defined in zephyr/dts/arm/st/f4/stm32f4.dtsi:390 */
			pwm {
				compatible = "st,stm32-pwm"; /* in zephyr/dts/arm/st/f4/stm32f4.dtsi:391 */
				status = "disabled";         /* in zephyr/dts/arm/st/f4/stm32f4.dtsi:392 */
				#pwm-cells = < 0x3 >;        /* in zephyr/dts/arm/st/f4/stm32f4.dtsi:393 */
			};

			/* node '/soc/timers@40010000/counter' defined in zephyr/dts/arm/st/f4/stm32f4.dtsi:396 */
			counter {
				compatible = "st,stm32-counter"; /* in zephyr/dts/arm/st/f4/stm32f4.dtsi:397 */
				status = "disabled";             /* in zephyr/dts/arm/st/f4/stm32f4.dtsi:398 */
			};

			/* node '/soc/timers@40010000/qdec' defined in zephyr/dts/arm/st/f4/stm32f4.dtsi:401 */
			qdec {
				compatible = "st,stm32-qdec";    /* in zephyr/dts/arm/st/f4/stm32f4.dtsi:402 */
				st,input-filter-level = < 0x0 >; /* in zephyr/dts/arm/st/f4/stm32f4.dtsi:403 */
				status = "disabled";             /* in zephyr/dts/arm/st/f4/stm32f4.dtsi:404 */
			};
		};

		/* node '/soc/timers@40000000' defined in zephyr/dts/arm/st/f4/stm32f4.dtsi:408 */
		timers2: timers@40000000 {
			compatible = "st,stm32-timers"; /* in zephyr/dts/arm/st/f4/stm32f4.dtsi:409 */
			reg = < 0x40000000 0x400 >;     /* in zephyr/dts/arm/st/f4/stm32f4.dtsi:410 */
			clocks = < &rcc 0x40 0x1 >,
			         < &rcc 0x15 0xff >;    /* in zephyr/dts/arm/st/f4/stm32f4.dtsi:411 */
			resets = < &rctl 0x400 >;       /* in zephyr/dts/arm/st/f4/stm32f4.dtsi:413 */
			interrupts = < 0x1c 0x0 >;      /* in zephyr/dts/arm/st/f4/stm32f4.dtsi:414 */
			interrupt-names = "global";     /* in zephyr/dts/arm/st/f4/stm32f4.dtsi:415 */
			st,prescaler = < 0x0 >;         /* in zephyr/dts/arm/st/f4/stm32f4.dtsi:416 */
			status = "disabled";            /* in zephyr/dts/arm/st/f4/stm32f4.dtsi:417 */

			/* node '/soc/timers@40000000/pwm' defined in zephyr/dts/arm/st/f4/stm32f4.dtsi:419 */
			pwm {
				compatible = "st,stm32-pwm"; /* in zephyr/dts/arm/st/f4/stm32f4.dtsi:420 */
				status = "disabled";         /* in zephyr/dts/arm/st/f4/stm32f4.dtsi:421 */
				#pwm-cells = < 0x3 >;        /* in zephyr/dts/arm/st/f4/stm32f4.dtsi:422 */
			};

			/* node '/soc/timers@40000000/counter' defined in zephyr/dts/arm/st/f4/stm32f4.dtsi:425 */
			counter {
				compatible = "st,stm32-counter"; /* in zephyr/dts/arm/st/f4/stm32f4.dtsi:426 */
				status = "disabled";             /* in zephyr/dts/arm/st/f4/stm32f4.dtsi:427 */
			};

			/* node '/soc/timers@40000000/qdec' defined in zephyr/dts/arm/st/f4/stm32f4.dtsi:430 */
			qdec {
				compatible = "st,stm32-qdec";    /* in zephyr/dts/arm/st/f4/stm32f4.dtsi:431 */
				st,input-filter-level = < 0x0 >; /* in zephyr/dts/arm/st/f4/stm32f4.dtsi:432 */
				status = "disabled";             /* in zephyr/dts/arm/st/f4/stm32f4.dtsi:433 */
			};
		};

		/* node '/soc/timers@40000400' defined in zephyr/dts/arm/st/f4/stm32f4.dtsi:437 */
		timers3: timers@40000400 {
			compatible = "st,stm32-timers"; /* in zephyr/dts/arm/st/f4/stm32f4.dtsi:438 */
			reg = < 0x40000400 0x400 >;     /* in zephyr/dts/arm/st/f4/stm32f4.dtsi:439 */
			clocks = < &rcc 0x40 0x2 >,
			         < &rcc 0x15 0xff >;    /* in zephyr/dts/arm/st/f4/stm32f4.dtsi:440 */
			resets = < &rctl 0x401 >;       /* in zephyr/dts/arm/st/f4/stm32f4.dtsi:442 */
			interrupts = < 0x1d 0x0 >;      /* in zephyr/dts/arm/st/f4/stm32f4.dtsi:443 */
			interrupt-names = "global";     /* in zephyr/dts/arm/st/f4/stm32f4.dtsi:444 */
			st,prescaler = < 0x0 >;         /* in zephyr/dts/arm/st/f4/stm32f4.dtsi:445 */
			status = "disabled";            /* in zephyr/dts/arm/st/f4/stm32f4.dtsi:446 */

			/* node '/soc/timers@40000400/pwm' defined in zephyr/dts/arm/st/f4/stm32f4.dtsi:448 */
			pwm {
				compatible = "st,stm32-pwm"; /* in zephyr/dts/arm/st/f4/stm32f4.dtsi:449 */
				status = "disabled";         /* in zephyr/dts/arm/st/f4/stm32f4.dtsi:450 */
				#pwm-cells = < 0x3 >;        /* in zephyr/dts/arm/st/f4/stm32f4.dtsi:451 */
			};

			/* node '/soc/timers@40000400/counter' defined in zephyr/dts/arm/st/f4/stm32f4.dtsi:454 */
			counter {
				compatible = "st,stm32-counter"; /* in zephyr/dts/arm/st/f4/stm32f4.dtsi:455 */
				status = "disabled";             /* in zephyr/dts/arm/st/f4/stm32f4.dtsi:456 */
			};

			/* node '/soc/timers@40000400/qdec' defined in zephyr/dts/arm/st/f4/stm32f4.dtsi:459 */
			qdec {
				compatible = "st,stm32-qdec";    /* in zephyr/dts/arm/st/f4/stm32f4.dtsi:460 */
				st,input-filter-level = < 0x0 >; /* in zephyr/dts/arm/st/f4/stm32f4.dtsi:461 */
				status = "disabled";             /* in zephyr/dts/arm/st/f4/stm32f4.dtsi:462 */
			};
		};

		/* node '/soc/timers@40000800' defined in zephyr/dts/arm/st/f4/stm32f4.dtsi:466 */
		timers4: timers@40000800 {
			compatible = "st,stm32-timers"; /* in zephyr/dts/arm/st/f4/stm32f4.dtsi:467 */
			reg = < 0x40000800 0x400 >;     /* in zephyr/dts/arm/st/f4/stm32f4.dtsi:468 */
			clocks = < &rcc 0x40 0x4 >,
			         < &rcc 0x15 0xff >;    /* in zephyr/dts/arm/st/f4/stm32f4.dtsi:469 */
			resets = < &rctl 0x402 >;       /* in zephyr/dts/arm/st/f4/stm32f4.dtsi:471 */
			interrupts = < 0x1e 0x0 >;      /* in zephyr/dts/arm/st/f4/stm32f4.dtsi:472 */
			interrupt-names = "global";     /* in zephyr/dts/arm/st/f4/stm32f4.dtsi:473 */
			st,prescaler = < 0x0 >;         /* in zephyr/dts/arm/st/f4/stm32f4.dtsi:474 */
			status = "disabled";            /* in zephyr/dts/arm/st/f4/stm32f4.dtsi:475 */

			/* node '/soc/timers@40000800/pwm' defined in zephyr/dts/arm/st/f4/stm32f4.dtsi:477 */
			pwm {
				compatible = "st,stm32-pwm"; /* in zephyr/dts/arm/st/f4/stm32f4.dtsi:478 */
				status = "disabled";         /* in zephyr/dts/arm/st/f4/stm32f4.dtsi:479 */
				#pwm-cells = < 0x3 >;        /* in zephyr/dts/arm/st/f4/stm32f4.dtsi:480 */
			};

			/* node '/soc/timers@40000800/counter' defined in zephyr/dts/arm/st/f4/stm32f4.dtsi:483 */
			counter {
				compatible = "st,stm32-counter"; /* in zephyr/dts/arm/st/f4/stm32f4.dtsi:484 */
				status = "disabled";             /* in zephyr/dts/arm/st/f4/stm32f4.dtsi:485 */
			};

			/* node '/soc/timers@40000800/qdec' defined in zephyr/dts/arm/st/f4/stm32f4.dtsi:488 */
			qdec {
				compatible = "st,stm32-qdec";    /* in zephyr/dts/arm/st/f4/stm32f4.dtsi:489 */
				st,input-filter-level = < 0x0 >; /* in zephyr/dts/arm/st/f4/stm32f4.dtsi:490 */
				status = "disabled";             /* in zephyr/dts/arm/st/f4/stm32f4.dtsi:491 */
			};
		};

		/* node '/soc/timers@40000c00' defined in zephyr/dts/arm/st/f4/stm32f4.dtsi:495 */
		timers5: timers@40000c00 {
			compatible = "st,stm32-timers"; /* in zephyr/dts/arm/st/f4/stm32f4.dtsi:496 */
			reg = < 0x40000c00 0x400 >;     /* in zephyr/dts/arm/st/f4/stm32f4.dtsi:497 */
			clocks = < &rcc 0x40 0x8 >,
			         < &rcc 0x15 0xff >;    /* in zephyr/dts/arm/st/f4/stm32f4.dtsi:498 */
			resets = < &rctl 0x403 >;       /* in zephyr/dts/arm/st/f4/stm32f4.dtsi:500 */
			interrupts = < 0x32 0x0 >;      /* in zephyr/dts/arm/st/f4/stm32f4.dtsi:501 */
			interrupt-names = "global";     /* in zephyr/dts/arm/st/f4/stm32f4.dtsi:502 */
			st,prescaler = < 0x0 >;         /* in zephyr/dts/arm/st/f4/stm32f4.dtsi:503 */
			status = "disabled";            /* in zephyr/dts/arm/st/f4/stm32f4.dtsi:504 */

			/* node '/soc/timers@40000c00/pwm' defined in zephyr/dts/arm/st/f4/stm32f4.dtsi:506 */
			pwm {
				compatible = "st,stm32-pwm"; /* in zephyr/dts/arm/st/f4/stm32f4.dtsi:507 */
				status = "disabled";         /* in zephyr/dts/arm/st/f4/stm32f4.dtsi:508 */
				#pwm-cells = < 0x3 >;        /* in zephyr/dts/arm/st/f4/stm32f4.dtsi:509 */
			};

			/* node '/soc/timers@40000c00/counter' defined in zephyr/dts/arm/st/f4/stm32f4.dtsi:512 */
			counter {
				compatible = "st,stm32-counter"; /* in zephyr/dts/arm/st/f4/stm32f4.dtsi:513 */
				status = "disabled";             /* in zephyr/dts/arm/st/f4/stm32f4.dtsi:514 */
			};

			/* node '/soc/timers@40000c00/qdec' defined in zephyr/dts/arm/st/f4/stm32f4.dtsi:517 */
			qdec {
				compatible = "st,stm32-qdec";    /* in zephyr/dts/arm/st/f4/stm32f4.dtsi:518 */
				st,input-filter-level = < 0x0 >; /* in zephyr/dts/arm/st/f4/stm32f4.dtsi:519 */
				status = "disabled";             /* in zephyr/dts/arm/st/f4/stm32f4.dtsi:520 */
			};
		};

		/* node '/soc/timers@40014000' defined in zephyr/dts/arm/st/f4/stm32f4.dtsi:524 */
		timers9: timers@40014000 {
			compatible = "st,stm32-timers"; /* in zephyr/dts/arm/st/f4/stm32f4.dtsi:525 */
			reg = < 0x40014000 0x400 >;     /* in zephyr/dts/arm/st/f4/stm32f4.dtsi:526 */
			clocks = < &rcc 0x44 0x10000 >,
			         < &rcc 0x16 0xff >;    /* in zephyr/dts/arm/st/f4/stm32f4.dtsi:527 */
			resets = < &rctl 0x490 >;       /* in zephyr/dts/arm/st/f4/stm32f4.dtsi:529 */
			interrupts = < 0x18 0x0 >;      /* in zephyr/dts/arm/st/f4/stm32f4.dtsi:530 */
			interrupt-names = "global";     /* in zephyr/dts/arm/st/f4/stm32f4.dtsi:531 */
			st,prescaler = < 0x0 >;         /* in zephyr/dts/arm/st/f4/stm32f4.dtsi:532 */
			status = "disabled";            /* in zephyr/dts/arm/st/f4/stm32f4.dtsi:533 */

			/* node '/soc/timers@40014000/pwm' defined in zephyr/dts/arm/st/f4/stm32f4.dtsi:535 */
			pwm {
				compatible = "st,stm32-pwm"; /* in zephyr/dts/arm/st/f4/stm32f4.dtsi:536 */
				status = "disabled";         /* in zephyr/dts/arm/st/f4/stm32f4.dtsi:537 */
				#pwm-cells = < 0x3 >;        /* in zephyr/dts/arm/st/f4/stm32f4.dtsi:538 */
			};

			/* node '/soc/timers@40014000/counter' defined in zephyr/dts/arm/st/f4/stm32f4.dtsi:541 */
			counter {
				compatible = "st,stm32-counter"; /* in zephyr/dts/arm/st/f4/stm32f4.dtsi:542 */
				status = "disabled";             /* in zephyr/dts/arm/st/f4/stm32f4.dtsi:543 */
			};
		};

		/* node '/soc/timers@40014400' defined in zephyr/dts/arm/st/f4/stm32f4.dtsi:547 */
		timers10: timers@40014400 {
			compatible = "st,stm32-timers"; /* in zephyr/dts/arm/st/f4/stm32f4.dtsi:548 */
			reg = < 0x40014400 0x400 >;     /* in zephyr/dts/arm/st/f4/stm32f4.dtsi:549 */
			clocks = < &rcc 0x44 0x20000 >,
			         < &rcc 0x16 0xff >;    /* in zephyr/dts/arm/st/f4/stm32f4.dtsi:550 */
			resets = < &rctl 0x491 >;       /* in zephyr/dts/arm/st/f4/stm32f4.dtsi:552 */
			interrupts = < 0x19 0x0 >;      /* in zephyr/dts/arm/st/f4/stm32f4.dtsi:553 */
			interrupt-names = "global";     /* in zephyr/dts/arm/st/f4/stm32f4.dtsi:554 */
			st,prescaler = < 0x0 >;         /* in zephyr/dts/arm/st/f4/stm32f4.dtsi:555 */
			status = "disabled";            /* in zephyr/dts/arm/st/f4/stm32f4.dtsi:556 */

			/* node '/soc/timers@40014400/pwm' defined in zephyr/dts/arm/st/f4/stm32f4.dtsi:558 */
			pwm {
				compatible = "st,stm32-pwm"; /* in zephyr/dts/arm/st/f4/stm32f4.dtsi:559 */
				status = "disabled";         /* in zephyr/dts/arm/st/f4/stm32f4.dtsi:560 */
				#pwm-cells = < 0x3 >;        /* in zephyr/dts/arm/st/f4/stm32f4.dtsi:561 */
			};

			/* node '/soc/timers@40014400/counter' defined in zephyr/dts/arm/st/f4/stm32f4.dtsi:564 */
			counter {
				compatible = "st,stm32-counter"; /* in zephyr/dts/arm/st/f4/stm32f4.dtsi:565 */
				status = "disabled";             /* in zephyr/dts/arm/st/f4/stm32f4.dtsi:566 */
			};
		};

		/* node '/soc/timers@40014800' defined in zephyr/dts/arm/st/f4/stm32f4.dtsi:570 */
		timers11: timers@40014800 {
			compatible = "st,stm32-timers"; /* in zephyr/dts/arm/st/f4/stm32f4.dtsi:571 */
			reg = < 0x40014800 0x400 >;     /* in zephyr/dts/arm/st/f4/stm32f4.dtsi:572 */
			clocks = < &rcc 0x44 0x40000 >,
			         < &rcc 0x16 0xff >;    /* in zephyr/dts/arm/st/f4/stm32f4.dtsi:573 */
			resets = < &rctl 0x492 >;       /* in zephyr/dts/arm/st/f4/stm32f4.dtsi:575 */
			interrupts = < 0x1a 0x0 >;      /* in zephyr/dts/arm/st/f4/stm32f4.dtsi:576 */
			interrupt-names = "global";     /* in zephyr/dts/arm/st/f4/stm32f4.dtsi:577 */
			st,prescaler = < 0x0 >;         /* in zephyr/dts/arm/st/f4/stm32f4.dtsi:578 */
			status = "disabled";            /* in zephyr/dts/arm/st/f4/stm32f4.dtsi:579 */

			/* node '/soc/timers@40014800/pwm' defined in zephyr/dts/arm/st/f4/stm32f4.dtsi:581 */
			pwm {
				compatible = "st,stm32-pwm"; /* in zephyr/dts/arm/st/f4/stm32f4.dtsi:582 */
				status = "disabled";         /* in zephyr/dts/arm/st/f4/stm32f4.dtsi:583 */
				#pwm-cells = < 0x3 >;        /* in zephyr/dts/arm/st/f4/stm32f4.dtsi:584 */
			};

			/* node '/soc/timers@40014800/counter' defined in zephyr/dts/arm/st/f4/stm32f4.dtsi:587 */
			counter {
				compatible = "st,stm32-counter"; /* in zephyr/dts/arm/st/f4/stm32f4.dtsi:588 */
				status = "disabled";             /* in zephyr/dts/arm/st/f4/stm32f4.dtsi:589 */
			};
		};

		/* node '/soc/rtc@40002800' defined in zephyr/dts/arm/st/f4/stm32f4.dtsi:593 */
		rtc: rtc@40002800 {
			compatible = "st,stm32-rtc";       /* in zephyr/dts/arm/st/f4/stm32f4.dtsi:594 */
			reg = < 0x40002800 0x400 >;        /* in zephyr/dts/arm/st/f4/stm32f4.dtsi:595 */
			interrupts = < 0x29 0x0 >;         /* in zephyr/dts/arm/st/f4/stm32f4.dtsi:596 */
			clocks = < &rcc 0x40 0x10000000 >; /* in zephyr/dts/arm/st/f4/stm32f4.dtsi:597 */
			prescaler = < 0x8000 >;            /* in zephyr/dts/arm/st/f4/stm32f4.dtsi:598 */
			alarms-count = < 0x2 >;            /* in zephyr/dts/arm/st/f4/stm32f4.dtsi:599 */
			alrm-exti-line = < 0x11 >;         /* in zephyr/dts/arm/st/f4/stm32f4.dtsi:600 */
			status = "disabled";               /* in zephyr/dts/arm/st/f4/stm32f4.dtsi:601 */

			/* node '/soc/rtc@40002800/backup_regs' defined in zephyr/dts/arm/st/f4/stm32f4.dtsi:603 */
			bbram: backup_regs {
				compatible = "st,stm32-bbram"; /* in zephyr/dts/arm/st/f4/stm32f4.dtsi:604 */
				st,backup-regs = < 0x14 >;     /* in zephyr/dts/arm/st/f4/stm32f4.dtsi:605 */
				status = "disabled";           /* in zephyr/dts/arm/st/f4/stm32f4.dtsi:606 */
			};
		};

		/* node '/soc/adc@40012000' defined in zephyr/dts/arm/st/f4/stm32f4.dtsi:610 */
		adc1: adc@40012000 {
			compatible = "st,stm32f4-adc",
			             "st,stm32-adc";                                 /* in zephyr/dts/arm/st/f4/stm32f4.dtsi:611 */
			reg = < 0x40012000 0x400 >;                                  /* in zephyr/dts/arm/st/f4/stm32f4.dtsi:612 */
			clocks = < &rcc 0x44 0x100 >;                                /* in zephyr/dts/arm/st/f4/stm32f4.dtsi:613 */
			clock-names = "adcx";                                        /* in zephyr/dts/arm/st/f4/stm32f4.dtsi:614 */
			interrupts = < 0x12 0x0 >;                                   /* in zephyr/dts/arm/st/f4/stm32f4.dtsi:615 */
			#io-channel-cells = < 0x1 >;                                 /* in zephyr/dts/arm/st/f4/stm32f4.dtsi:616 */
			st,adc-resolutions = < 0xc 0xa 0x8 0x6 >;                    /* in zephyr/dts/arm/st/f4/stm32f4.dtsi:617 */
			sampling-times = < 0x3 0xf 0x1c 0x38 0x54 0x70 0x90 0x1e0 >; /* in zephyr/dts/arm/st/f4/stm32f4.dtsi:618 */
			st,adc-clock-source = "SYNC";                                /* in zephyr/dts/arm/st/f4/stm32f4.dtsi:619 */
			st,adc-sequencer = "programmable";                           /* in zephyr/dts/arm/st/f4/stm32f4.dtsi:620 */
			st,adc-oversampler = "none";                                 /* in zephyr/dts/arm/st/f4/stm32f4.dtsi:621 */
			st,adc-internal-regulator = "none";                          /* in zephyr/dts/arm/st/f4/stm32f4.dtsi:622 */
			st,adc-has-injected-support;                                 /* in zephyr/dts/arm/st/f4/stm32f4.dtsi:623 */
			status = "disabled";                                         /* in zephyr/dts/arm/st/f4/stm32f4.dtsi:624 */
			phandle = < 0xe >;                                           /* in zephyr/dts/arm/st/f4/stm32f4.dtsi:680 */
		};

		/* node '/soc/dma@40026000' defined in zephyr/dts/arm/st/f4/stm32f4.dtsi:627 */
		dma1: dma@40026000 {
			compatible = "st,stm32-dma-v1";                                                      /* in zephyr/dts/arm/st/f4/stm32f4.dtsi:628 */
			#dma-cells = < 0x4 >;                                                                /* in zephyr/dts/arm/st/f4/stm32f4.dtsi:629 */
			reg = < 0x40026000 0x400 >;                                                          /* in zephyr/dts/arm/st/f4/stm32f4.dtsi:630 */
			interrupts = < 0xb 0x0 0xc 0x0 0xd 0x0 0xe 0x0 0xf 0x0 0x10 0x0 0x11 0x0 0x2f 0x0 >; /* in zephyr/dts/arm/st/f4/stm32f4.dtsi:631 */
			clocks = < &rcc 0x30 0x200000 >;                                                     /* in zephyr/dts/arm/st/f4/stm32f4.dtsi:632 */
			status = "disabled";                                                                 /* in zephyr/dts/arm/st/f4/stm32f4.dtsi:633 */
			phandle = < 0x8 >;                                                                   /* in zephyr/dts/arm/st/f4/stm32f401.dtsi:61 */
		};

		/* node '/soc/dma@40026400' defined in zephyr/dts/arm/st/f4/stm32f4.dtsi:636 */
		dma2: dma@40026400 {
			compatible = "st,stm32-dma-v1";                                                           /* in zephyr/dts/arm/st/f4/stm32f4.dtsi:637 */
			#dma-cells = < 0x4 >;                                                                     /* in zephyr/dts/arm/st/f4/stm32f4.dtsi:638 */
			reg = < 0x40026400 0x400 >;                                                               /* in zephyr/dts/arm/st/f4/stm32f4.dtsi:639 */
			interrupts = < 0x38 0x0 0x39 0x0 0x3a 0x0 0x3b 0x0 0x3c 0x0 0x44 0x0 0x45 0x0 0x46 0x0 >; /* in zephyr/dts/arm/st/f4/stm32f4.dtsi:640 */
			clocks = < &rcc 0x30 0x400000 >;                                                          /* in zephyr/dts/arm/st/f4/stm32f4.dtsi:641 */
			st,mem2mem;                                                                               /* in zephyr/dts/arm/st/f4/stm32f4.dtsi:642 */
			status = "disabled";                                                                      /* in zephyr/dts/arm/st/f4/stm32f4.dtsi:643 */
		};

		/* node '/soc/sdmmc@40012c00' defined in zephyr/dts/arm/st/f4/stm32f4.dtsi:646 */
		sdmmc1: sdmmc@40012c00 {
			compatible = "st,stm32-sdmmc"; /* in zephyr/dts/arm/st/f4/stm32f4.dtsi:647 */
			reg = < 0x40012c00 0x400 >;    /* in zephyr/dts/arm/st/f4/stm32f4.dtsi:648 */
			clocks = < &rcc 0x44 0x800 >,
			         < &rcc 0x7 0xff >;    /* in zephyr/dts/arm/st/f4/stm32f4.dtsi:649 */
			resets = < &rctl 0x48b >;      /* in zephyr/dts/arm/st/f4/stm32f4.dtsi:651 */
			interrupts = < 0x31 0x0 >;     /* in zephyr/dts/arm/st/f4/stm32f4.dtsi:652 */
			status = "disabled";           /* in zephyr/dts/arm/st/f4/stm32f4.dtsi:653 */
		};

		/* node '/soc/spi@40003800' defined in zephyr/dts/arm/st/f4/stm32f401.dtsi:21 */
		spi2: spi@40003800 {
			compatible = "st,stm32-spi";            /* in zephyr/dts/arm/st/f4/stm32f401.dtsi:22 */
			#address-cells = < 0x1 >;               /* in zephyr/dts/arm/st/f4/stm32f401.dtsi:23 */
			#size-cells = < 0x0 >;                  /* in zephyr/dts/arm/st/f4/stm32f401.dtsi:24 */
			reg = < 0x40003800 0x400 >;             /* in zephyr/dts/arm/st/f4/stm32f401.dtsi:25 */
			clocks = < &rcc 0x40 0x4000 >;          /* in zephyr/dts/arm/st/f4/stm32f401.dtsi:26 */
			interrupts = < 0x24 0x0 >;              /* in zephyr/dts/arm/st/f4/stm32f401.dtsi:27 */
			st,spi-data-width = "limited-8-16-bit"; /* in zephyr/dts/arm/st/f4/stm32f401.dtsi:28 */
			status = "disabled";                    /* in zephyr/dts/arm/st/f4/stm32f401.dtsi:29 */
		};

		/* node '/soc/spi@40003c00' defined in zephyr/dts/arm/st/f4/stm32f401.dtsi:32 */
		spi3: spi@40003c00 {
			compatible = "st,stm32-spi";            /* in zephyr/dts/arm/st/f4/stm32f401.dtsi:33 */
			#address-cells = < 0x1 >;               /* in zephyr/dts/arm/st/f4/stm32f401.dtsi:34 */
			#size-cells = < 0x0 >;                  /* in zephyr/dts/arm/st/f4/stm32f401.dtsi:35 */
			reg = < 0x40003c00 0x400 >;             /* in zephyr/dts/arm/st/f4/stm32f401.dtsi:36 */
			clocks = < &rcc 0x40 0x8000 >;          /* in zephyr/dts/arm/st/f4/stm32f401.dtsi:37 */
			interrupts = < 0x33 0x0 >;              /* in zephyr/dts/arm/st/f4/stm32f401.dtsi:38 */
			st,spi-data-width = "limited-8-16-bit"; /* in zephyr/dts/arm/st/f4/stm32f401.dtsi:39 */
			status = "disabled";                    /* in zephyr/dts/arm/st/f4/stm32f401.dtsi:40 */
		};

		/* node '/soc/spi@40013400' defined in zephyr/dts/arm/st/f4/stm32f401.dtsi:43 */
		spi4: spi@40013400 {
			compatible = "st,stm32-spi";            /* in zephyr/dts/arm/st/f4/stm32f401.dtsi:44 */
			#address-cells = < 0x1 >;               /* in zephyr/dts/arm/st/f4/stm32f401.dtsi:45 */
			#size-cells = < 0x0 >;                  /* in zephyr/dts/arm/st/f4/stm32f401.dtsi:46 */
			reg = < 0x40013400 0x400 >;             /* in zephyr/dts/arm/st/f4/stm32f401.dtsi:47 */
			clocks = < &rcc 0x44 0x2000 >;          /* in zephyr/dts/arm/st/f4/stm32f401.dtsi:48 */
			interrupts = < 0x54 0x0 >;              /* in zephyr/dts/arm/st/f4/stm32f401.dtsi:49 */
			st,spi-data-width = "limited-8-16-bit"; /* in zephyr/dts/arm/st/f4/stm32f401.dtsi:50 */
			status = "disabled";                    /* in zephyr/dts/arm/st/f4/stm32f401.dtsi:51 */
		};

		/* node '/soc/i2s@40003800' defined in zephyr/dts/arm/st/f4/stm32f401.dtsi:54 */
		i2s2: i2s@40003800 {
			compatible = "st,stm32-i2s";        /* in zephyr/dts/arm/st/f4/stm32f401.dtsi:55 */
			#address-cells = < 0x1 >;           /* in zephyr/dts/arm/st/f4/stm32f401.dtsi:56 */
			#size-cells = < 0x0 >;              /* in zephyr/dts/arm/st/f4/stm32f401.dtsi:57 */
			reg = < 0x40003800 0x400 >;         /* in zephyr/dts/arm/st/f4/stm32f401.dtsi:58 */
			clocks = < &rcc 0x40 0x4000 >;      /* in zephyr/dts/arm/st/f4/stm32f401.dtsi:59 */
			interrupts = < 0x24 0x0 >;          /* in zephyr/dts/arm/st/f4/stm32f401.dtsi:60 */
			dmas = < &dma1 0x4 0x0 0x400 0x3 >,
			       < &dma1 0x3 0x0 0x400 0x3 >; /* in zephyr/dts/arm/st/f4/stm32f401.dtsi:61 */
			dma-names = "tx",
			            "rx";                   /* in zephyr/dts/arm/st/f4/stm32f401.dtsi:63 */
			status = "disabled";                /* in zephyr/dts/arm/st/f4/stm32f401.dtsi:64 */
		};

		/* node '/soc/i2s@40003c00' defined in zephyr/dts/arm/st/f4/stm32f401.dtsi:67 */
		i2s3: i2s@40003c00 {
			compatible = "st,stm32-i2s";        /* in zephyr/dts/arm/st/f4/stm32f401.dtsi:68 */
			#address-cells = < 0x1 >;           /* in zephyr/dts/arm/st/f4/stm32f401.dtsi:69 */
			#size-cells = < 0x0 >;              /* in zephyr/dts/arm/st/f4/stm32f401.dtsi:70 */
			reg = < 0x40003c00 0x400 >;         /* in zephyr/dts/arm/st/f4/stm32f401.dtsi:71 */
			clocks = < &rcc 0x40 0x8000 >;      /* in zephyr/dts/arm/st/f4/stm32f401.dtsi:72 */
			interrupts = < 0x33 0x0 >;          /* in zephyr/dts/arm/st/f4/stm32f401.dtsi:73 */
			dmas = < &dma1 0x5 0x0 0x400 0x3 >,
			       < &dma1 0x0 0x0 0x400 0x3 >; /* in zephyr/dts/arm/st/f4/stm32f401.dtsi:74 */
			dma-names = "tx",
			            "rx";                   /* in zephyr/dts/arm/st/f4/stm32f401.dtsi:76 */
			status = "disabled";                /* in zephyr/dts/arm/st/f4/stm32f401.dtsi:77 */
		};
	};

	/* node '/cpus' defined in zephyr/dts/arm/st/f4/stm32f4.dtsi:30 */
	cpus {
		#address-cells = < 0x1 >; /* in zephyr/dts/arm/st/f4/stm32f4.dtsi:31 */
		#size-cells = < 0x0 >;    /* in zephyr/dts/arm/st/f4/stm32f4.dtsi:32 */

		/* node '/cpus/cpu@0' defined in zephyr/dts/arm/st/f4/stm32f4.dtsi:34 */
		cpu0: cpu@0 {
			device_type = "cpu";           /* in zephyr/dts/arm/st/f4/stm32f4.dtsi:35 */
			compatible = "arm,cortex-m4f"; /* in zephyr/dts/arm/st/f4/stm32f4.dtsi:36 */
			reg = < 0x0 >;                 /* in zephyr/dts/arm/st/f4/stm32f4.dtsi:37 */
			cpu-power-states = < &stop >;  /* in zephyr/dts/arm/st/f4/stm32f4.dtsi:38 */
		};

		/* node '/cpus/power-states' defined in zephyr/dts/arm/st/f4/stm32f4.dtsi:41 */
		power-states {

			/* node '/cpus/power-states/stop' defined in zephyr/dts/arm/st/f4/stm32f4.dtsi:42 */
			stop: stop {
				compatible = "zephyr,power-state";    /* in zephyr/dts/arm/st/f4/stm32f4.dtsi:43 */
				power-state-name = "suspend-to-idle"; /* in zephyr/dts/arm/st/f4/stm32f4.dtsi:44 */
				min-residency-us = < 0x190 >;         /* in zephyr/dts/arm/st/f4/stm32f4.dtsi:51 */
				exit-latency-us = < 0x12c >;          /* in zephyr/dts/arm/st/f4/stm32f4.dtsi:52 */
				phandle = < 0x9 >;                    /* in zephyr/dts/arm/st/f4/stm32f4.dtsi:38 */
			};
		};
	};

	/* node '/memory@20000000' defined in zephyr/dts/arm/st/f4/stm32f4.dtsi:57 */
	sram0: memory@20000000 {
		compatible = "zephyr,memory-region",
		             "mmio-sram";            /* in zephyr/dts/arm/st/f4/stm32f4.dtsi:58 */
		zephyr,memory-region = "SRAM0";      /* in zephyr/dts/arm/st/f4/stm32f4.dtsi:59 */
		reg = < 0x20000000 0x18000 >;        /* in zephyr/dts/arm/st/f4/stm32f401Xe.dtsi:11 */
	};

	/* node '/clocks' defined in zephyr/dts/arm/st/f4/stm32f4.dtsi:62 */
	clocks {

		/* node '/clocks/clk-hse' defined in zephyr/dts/arm/st/f4/stm32f4.dtsi:63 */
		clk_hse: clk-hse {
			#clock-cells = < 0x0 >;            /* in zephyr/dts/arm/st/f4/stm32f4.dtsi:64 */
			compatible = "st,stm32-hse-clock"; /* in zephyr/dts/arm/st/f4/stm32f4.dtsi:65 */
			clock-frequency = < 0x17d7840 >;   /* in ../STM32_F401_Basic_Framework/boards/others/stm32_f401_dev/stm32_f401_dev.dts:55 */
			status = "okay";                   /* in ../STM32_F401_Basic_Framework/boards/others/stm32_f401_dev/stm32_f401_dev.dts:56 */
			phandle = < 0xa >;                 /* in ../STM32_F401_Basic_Framework/boards/others/stm32_f401_dev/stm32_f401_dev.dts:64 */
		};

		/* node '/clocks/clk-hsi' defined in zephyr/dts/arm/st/f4/stm32f4.dtsi:69 */
		clk_hsi: clk-hsi {
			#clock-cells = < 0x0 >;         /* in zephyr/dts/arm/st/f4/stm32f4.dtsi:70 */
			compatible = "fixed-clock";     /* in zephyr/dts/arm/st/f4/stm32f4.dtsi:71 */
			clock-frequency = < 0xf42400 >; /* in zephyr/dts/arm/st/f4/stm32f4.dtsi:72 */
			status = "disabled";            /* in zephyr/dts/arm/st/f4/stm32f4.dtsi:73 */
		};

		/* node '/clocks/clk-lse' defined in zephyr/dts/arm/st/f4/stm32f4.dtsi:76 */
		clk_lse: clk-lse {
			#clock-cells = < 0x0 >;       /* in zephyr/dts/arm/st/f4/stm32f4.dtsi:77 */
			compatible = "fixed-clock";   /* in zephyr/dts/arm/st/f4/stm32f4.dtsi:78 */
			clock-frequency = < 0x8000 >; /* in zephyr/dts/arm/st/f4/stm32f4.dtsi:79 */
			status = "disabled";          /* in zephyr/dts/arm/st/f4/stm32f4.dtsi:80 */
		};

		/* node '/clocks/clk-lsi' defined in zephyr/dts/arm/st/f4/stm32f4.dtsi:83 */
		clk_lsi: clk-lsi {
			#clock-cells = < 0x0 >;       /* in zephyr/dts/arm/st/f4/stm32f4.dtsi:84 */
			compatible = "fixed-clock";   /* in zephyr/dts/arm/st/f4/stm32f4.dtsi:85 */
			clock-frequency = < 0x7d00 >; /* in zephyr/dts/arm/st/f4/stm32f4.dtsi:86 */
			status = "okay";              /* in ../STM32_F401_Basic_Framework/boards/others/stm32_f401_dev/stm32_f401_dev.dts:51 */
		};

		/* node '/clocks/pll' defined in zephyr/dts/arm/st/f4/stm32f4.dtsi:90 */
		pll: pll {
			#clock-cells = < 0x0 >;              /* in zephyr/dts/arm/st/f4/stm32f4.dtsi:91 */
			compatible = "st,stm32fx-pll-clock"; /* in zephyr/dts/arm/st/f4/stm32f4.dtsi:92 */
			div-m = < 0x19 >;                    /* in ../STM32_F401_Basic_Framework/boards/others/stm32_f401_dev/stm32_f401_dev.dts:60 */
			mul-n = < 0x150 >;                   /* in ../STM32_F401_Basic_Framework/boards/others/stm32_f401_dev/stm32_f401_dev.dts:61 */
			div-p = < 0x4 >;                     /* in ../STM32_F401_Basic_Framework/boards/others/stm32_f401_dev/stm32_f401_dev.dts:62 */
			div-q = < 0x7 >;                     /* in ../STM32_F401_Basic_Framework/boards/others/stm32_f401_dev/stm32_f401_dev.dts:63 */
			clocks = < &clk_hse >;               /* in ../STM32_F401_Basic_Framework/boards/others/stm32_f401_dev/stm32_f401_dev.dts:64 */
			status = "okay";                     /* in ../STM32_F401_Basic_Framework/boards/others/stm32_f401_dev/stm32_f401_dev.dts:65 */
			phandle = < 0x2 >;                   /* in ../STM32_F401_Basic_Framework/boards/others/stm32_f401_dev/stm32_f401_dev.dts:69 */
		};

		/* node '/clocks/plli2s' defined in zephyr/dts/arm/st/f4/stm32f401.dtsi:11 */
		plli2s: plli2s {
			#clock-cells = < 0x0 >;              /* in zephyr/dts/arm/st/f4/stm32f401.dtsi:12 */
			compatible = "st,stm32fx-pll-clock"; /* in zephyr/dts/arm/st/f4/stm32f401.dtsi:13 */
			status = "disabled";                 /* in zephyr/dts/arm/st/f4/stm32f401.dtsi:14 */
		};
	};

	/* node '/mcos' defined in zephyr/dts/arm/st/f4/stm32f4.dtsi:97 */
	mcos {

		/* node '/mcos/mco1' defined in zephyr/dts/arm/st/f4/stm32f4.dtsi:98 */
		mco1: mco1 {
			compatible = "st,stm32-clock-mco"; /* in zephyr/dts/arm/st/f4/stm32f4.dtsi:99 */
			clock-names = "clksel";            /* in zephyr/dts/arm/st/f4/stm32f4.dtsi:100 */
			status = "disabled";               /* in zephyr/dts/arm/st/f4/stm32f4.dtsi:101 */
		};

		/* node '/mcos/mco2' defined in zephyr/dts/arm/st/f4/stm32f4.dtsi:104 */
		mco2: mco2 {
			compatible = "st,stm32-clock-mco"; /* in zephyr/dts/arm/st/f4/stm32f4.dtsi:105 */
			clock-names = "clksel";            /* in zephyr/dts/arm/st/f4/stm32f4.dtsi:106 */
			status = "disabled";               /* in zephyr/dts/arm/st/f4/stm32f4.dtsi:107 */
		};
	};

	/* node '/power@40007000' defined in zephyr/dts/arm/st/f4/stm32f4.dtsi:657 */
	pwr: power@40007000 {
		compatible = "st,stm32-pwr"; /* in zephyr/dts/arm/st/f4/stm32f4.dtsi:658 */
		reg = < 0x40007000 0x400 >;  /* in zephyr/dts/arm/st/f4/stm32f4.dtsi:659 */
		status = "disabled";         /* in zephyr/dts/arm/st/f4/stm32f4.dtsi:660 */
		wkup-pins-nb = < 0x1 >;      /* in zephyr/dts/arm/st/f4/stm32f4.dtsi:662 */
		#address-cells = < 0x1 >;    /* in zephyr/dts/arm/st/f4/stm32f4.dtsi:664 */
		#size-cells = < 0x0 >;       /* in zephyr/dts/arm/st/f4/stm32f4.dtsi:665 */

		/* node '/power@40007000/wkup-pin@1' defined in zephyr/dts/arm/st/f4/stm32f4.dtsi:667 */
		wkup-pin@1 {
			reg = < 0x1 >;                   /* in zephyr/dts/arm/st/f4/stm32f4.dtsi:668 */
			wkup-gpios = < &gpioa 0x0 0x1 >; /* in zephyr/dts/arm/st/f4/stm32f4.dtsi:669 */
		};
	};

	/* node '/dietemp' defined in zephyr/dts/arm/st/f4/stm32f4.dtsi:673 */
	die_temp: dietemp {
		compatible = "st,stm32-temp-cal"; /* in zephyr/dts/arm/st/f4/stm32f4.dtsi:674 */
		nvmem-cells = < &ts_cal1_otp >,
		              < &ts_cal2_otp >;   /* in zephyr/dts/arm/st/f4/stm32f4.dtsi:675 */
		nvmem-cell-names = "TS_CAL1",
		                   "TS_CAL2";     /* in zephyr/dts/arm/st/f4/stm32f4.dtsi:676 */
		ts-cal1-temp = < 0x1e >;          /* in zephyr/dts/arm/st/f4/stm32f4.dtsi:677 */
		ts-cal2-temp = < 0x6e >;          /* in zephyr/dts/arm/st/f4/stm32f4.dtsi:678 */
		ts-cal-vrefanalog = < 0xce4 >;    /* in zephyr/dts/arm/st/f4/stm32f4.dtsi:679 */
		io-channels = < &adc1 0x10 >;     /* in zephyr/dts/arm/st/f4/stm32f4.dtsi:680 */
		status = "disabled";              /* in zephyr/dts/arm/st/f4/stm32f4.dtsi:681 */
	};

	/* node '/vref' defined in zephyr/dts/arm/st/f4/stm32f4.dtsi:684 */
	vref: vref {
		compatible = "st,stm32-vref";   /* in zephyr/dts/arm/st/f4/stm32f4.dtsi:685 */
		nvmem-cells = < &vrefint_otp >; /* in zephyr/dts/arm/st/f4/stm32f4.dtsi:686 */
		vrefint-cal-mv = < 0xce4 >;     /* in zephyr/dts/arm/st/f4/stm32f4.dtsi:687 */
		io-channels = < &adc1 0x11 >;   /* in zephyr/dts/arm/st/f4/stm32f4.dtsi:688 */
		status = "disabled";            /* in zephyr/dts/arm/st/f4/stm32f4.dtsi:689 */
	};

	/* node '/vbat' defined in zephyr/dts/arm/st/f4/stm32f4.dtsi:692 */
	vbat: vbat {
		compatible = "st,stm32-vbat"; /* in zephyr/dts/arm/st/f4/stm32f4.dtsi:693 */
		ratio = < 0x4 >;              /* in zephyr/dts/arm/st/f4/stm32f4.dtsi:694 */
		io-channels = < &adc1 0x12 >; /* in zephyr/dts/arm/st/f4/stm32f4.dtsi:695 */
		status = "disabled";          /* in zephyr/dts/arm/st/f4/stm32f4.dtsi:696 */
	};

	/* node '/otgfs_phy' defined in zephyr/dts/arm/st/f4/stm32f4.dtsi:699 */
	otgfs_phy: otgfs_phy {
		compatible = "usb-nop-xceiv"; /* in zephyr/dts/arm/st/f4/stm32f4.dtsi:700 */
		#phy-cells = < 0x0 >;         /* in zephyr/dts/arm/st/f4/stm32f4.dtsi:701 */
		phandle = < 0x7 >;            /* in zephyr/dts/arm/st/f4/stm32f4.dtsi:373 */
	};

	/* node '/smbus1' defined in zephyr/dts/arm/st/f4/stm32f4.dtsi:704 */
	smbus1: smbus1 {
		compatible = "st,stm32-smbus"; /* in zephyr/dts/arm/st/f4/stm32f4.dtsi:705 */
		#address-cells = < 0x1 >;      /* in zephyr/dts/arm/st/f4/stm32f4.dtsi:706 */
		#size-cells = < 0x0 >;         /* in zephyr/dts/arm/st/f4/stm32f4.dtsi:707 */
		i2c = < &i2c1 >;               /* in zephyr/dts/arm/st/f4/stm32f4.dtsi:708 */
		status = "disabled";           /* in zephyr/dts/arm/st/f4/stm32f4.dtsi:709 */
	};

	/* node '/smbus2' defined in zephyr/dts/arm/st/f4/stm32f4.dtsi:712 */
	smbus2: smbus2 {
		compatible = "st,stm32-smbus"; /* in zephyr/dts/arm/st/f4/stm32f4.dtsi:713 */
		#address-cells = < 0x1 >;      /* in zephyr/dts/arm/st/f4/stm32f4.dtsi:714 */
		#size-cells = < 0x0 >;         /* in zephyr/dts/arm/st/f4/stm32f4.dtsi:715 */
		i2c = < &i2c2 >;               /* in zephyr/dts/arm/st/f4/stm32f4.dtsi:716 */
		status = "disabled";           /* in zephyr/dts/arm/st/f4/stm32f4.dtsi:717 */
	};

	/* node '/smbus3' defined in zephyr/dts/arm/st/f4/stm32f4.dtsi:720 */
	smbus3: smbus3 {
		compatible = "st,stm32-smbus"; /* in zephyr/dts/arm/st/f4/stm32f4.dtsi:721 */
		#address-cells = < 0x1 >;      /* in zephyr/dts/arm/st/f4/stm32f4.dtsi:722 */
		#size-cells = < 0x0 >;         /* in zephyr/dts/arm/st/f4/stm32f4.dtsi:723 */
		i2c = < &i2c3 >;               /* in zephyr/dts/arm/st/f4/stm32f4.dtsi:724 */
		status = "disabled";           /* in zephyr/dts/arm/st/f4/stm32f4.dtsi:725 */
	};

	/* node '/leds' defined in ../STM32_F401_Basic_Framework/boards/others/stm32_f401_dev/stm32_f401_dev.dts:24 */
	leds {
		compatible = "gpio-leds"; /* in ../STM32_F401_Basic_Framework/boards/others/stm32_f401_dev/stm32_f401_dev.dts:25 */

		/* node '/leds/led-1' defined in ../STM32_F401_Basic_Framework/boards/others/stm32_f401_dev/stm32_f401_dev.dts:27 */
		user_led: led-1 {
			gpios = < &gpioc 0xd 0x1 >; /* in ../STM32_F401_Basic_Framework/boards/others/stm32_f401_dev/stm32_f401_dev.dts:28 */
			label = "LD";               /* in ../STM32_F401_Basic_Framework/boards/others/stm32_f401_dev/stm32_f401_dev.dts:29 */
		};
	};

	/* node '/gpio_keys' defined in ../STM32_F401_Basic_Framework/boards/others/stm32_f401_dev/stm32_f401_dev.dts:33 */
	gpio_keys {
		compatible = "gpio-keys"; /* in ../STM32_F401_Basic_Framework/boards/others/stm32_f401_dev/stm32_f401_dev.dts:34 */

		/* node '/gpio_keys/button-1' defined in ../STM32_F401_Basic_Framework/boards/others/stm32_f401_dev/stm32_f401_dev.dts:36 */
		user_button0: button-1 {
			gpios = < &gpioc 0x0 0x11 >; /* in ../STM32_F401_Basic_Framework/boards/others/stm32_f401_dev/stm32_f401_dev.dts:37 */
			zephyr,code = < 0xb >;       /* in ../STM32_F401_Basic_Framework/boards/others/stm32_f401_dev/stm32_f401_dev.dts:38 */
			label = "KEY0";              /* in ../STM32_F401_Basic_Framework/boards/others/stm32_f401_dev/stm32_f401_dev.dts:39 */
		};

		/* node '/gpio_keys/button-2' defined in ../STM32_F401_Basic_Framework/boards/others/stm32_f401_dev/stm32_f401_dev.dts:42 */
		user_button1: button-2 {
			gpios = < &gpioc 0x1 0x11 >; /* in ../STM32_F401_Basic_Framework/boards/others/stm32_f401_dev/stm32_f401_dev.dts:43 */
			zephyr,code = < 0x2 >;       /* in ../STM32_F401_Basic_Framework/boards/others/stm32_f401_dev/stm32_f401_dev.dts:44 */
			label = "KEY1";              /* in ../STM32_F401_Basic_Framework/boards/others/stm32_f401_dev/stm32_f401_dev.dts:45 */
		};
	};
};
